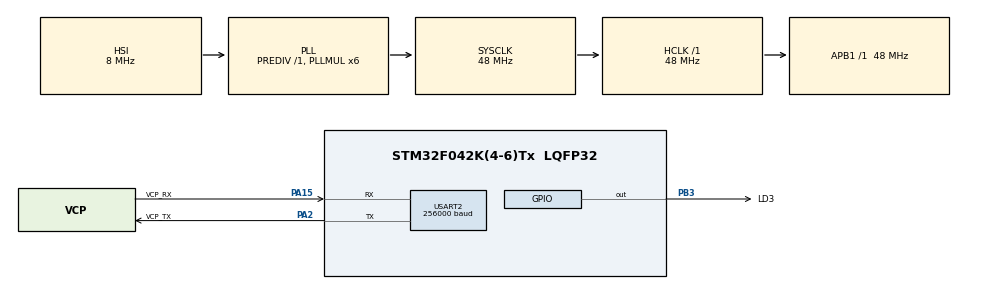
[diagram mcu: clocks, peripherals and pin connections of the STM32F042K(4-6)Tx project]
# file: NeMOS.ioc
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ADC.ContinuousConvMode=ENABLE
ADC.DMAContinuousRequests=ENABLE
ADC.SamplingTime=ADC_SAMPLETIME_239CYCLES_5
Dma.ADC.0.Direction=DMA_PERIPH_TO_MEMORY
Dma.ADC.0.Instance=DMA1_Channel1
Dma.ADC.0.MemDataAlignment=DMA_MDATAALIGN_HALFWORD
Dma.ADC.0.MemInc=DMA_MINC_ENABLE
Dma.ADC.0.Mode=DMA_CIRCULAR
Dma.ADC.0.PeriphDataAlignment=DMA_PDATAALIGN_HALFWORD
Dma.ADC.0.PeriphInc=DMA_PINC_DISABLE
Dma.ADC.0.Priority=DMA_PRIORITY_LOW
Dma.Request0=ADC
Mcu.Family=STM32F0
Mcu.Name=STM32F042K(4-6)Tx
Mcu.Package=LQFP32
Mcu.UserConstants=SYS_TICK_HZ,1000;ADC_CHAN_NO,3
NVIC.DMA1_Channel1_IRQn=true\:0\:0\:false\:false\:true\:false
PA13.GPIO_Label=SWDIO
PA13.Mode=Serial_Wire
PA13.Signal=SYS_SWDIO
PA14.GPIO_Label=SWCLK
PA14.Mode=Serial_Wire
PA14.Signal=SYS_SWCLK
PA15.GPIO_Label=VCP_RX
PA15.Mode=Asynchronous
PA15.Signal=USART2_RX
PA2.GPIO_Label=VCP_TX
PA2.Mode=Asynchronous
PA2.Signal=USART2_TX
PB3.GPIO_Label=LD3
PB3.Signal=GPIO_Output
PF0-OSC_IN.GPIO_Label=MCO
PF0-OSC_IN.Mode=HSE-External-Clock-Source
PF0-OSC_IN.Signal=RCC_OSC_IN
ProjectManager.HeapSize=0x200
ProjectManager.StackSize=0x400
ProjectManager.TargetToolchain=MDK-ARM V5
RCC.AHBFreq_Value=48000000
RCC.APB1Freq_Value=48000000
RCC.APB1TimFreq_Value=48000000
RCC.HCLKFreq_Value=48000000
RCC.PLLMUL=RCC_PLL_MUL6
RCC.SYSCLKFreq_VALUE=48000000
RCC.SYSCLKSource=RCC_SYSCLKSOURCE_PLLCLK
USART2.BaudRate=256000
USART2.VirtualMode-Asynchronous=VM_ASYNC
USART2.WordLength=WORDLENGTH_8B
VP_ADC_TempSens_Input.Mode=IN-TempSens
VP_ADC_Vbat_Input.Mode=IN-Vbat
VP_ADC_Vref_Input.Mode=IN-Vrefint
board=NUCLEO-F042K6

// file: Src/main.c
/**
  ******************************************************************************
  * @file           : main.c
  * @brief          : Main program body
  ******************************************************************************
  ** This notice applies to any and all portions of this file
  * that are not between comment pairs USER CODE BEGIN and
  * USER CODE END. Other portions of this file, whether
  * inserted by the user or by software development tools
  * are owned by their respective copyright owners.
  *
  * COPYRIGHT(c) 2018 STMicroelectronics
  *
  * Redistribution and use in source and binary forms, with or without modification,
  * are permitted provided that the following conditions are met:
  *   1. Redistributions of source code must retain the above copyright notice,
  *      this list of conditions and the following disclaimer.
  *   2. Redistributions in binary form must reproduce the above copyright notice,
  *      this list of conditions and the following disclaimer in the documentation
  *      and/or other materials provided with the distribution.
  *   3. Neither the name of STMicroelectronics nor the names of its contributors
  *      may be used to endorse or promote products derived from this software
  *      without specific prior written permission.
  *
  * THIS SOFTWARE IS PROVIDED BY THE COPYRIGHT HOLDERS AND CONTRIBUTORS "AS IS"
  * AND ANY EXPRESS OR IMPLIED WARRANTIES, INCLUDING, BUT NOT LIMITED TO, THE
  * IMPLIED WARRANTIES OF MERCHANTABILITY AND FITNESS FOR A PARTICULAR PURPOSE ARE
  * DISCLAIMED. IN NO EVENT SHALL THE COPYRIGHT HOLDER OR CONTRIBUTORS BE LIABLE
  * FOR ANY DIRECT, INDIRECT, INCIDENTAL, SPECIAL, EXEMPLARY, OR CONSEQUENTIAL
  * DAMAGES (INCLUDING, BUT NOT LIMITED TO, PROCUREMENT OF SUBSTITUTE GOODS OR
  * SERVICES; LOSS OF USE, DATA, OR PROFITS; OR BUSINESS INTERRUPTION) HOWEVER
  * CAUSED AND ON ANY THEORY OF LIABILITY, WHETHER IN CONTRACT, STRICT LIABILITY,
  * OR TORT (INCLUDING NEGLIGENCE OR OTHERWISE) ARISING IN ANY WAY OUT OF THE USE
  * OF THIS SOFTWARE, EVEN IF ADVISED OF THE POSSIBILITY OF SUCH DAMAGE.
  *
  ******************************************************************************
  */
#include "main.h"
#include "stm32f0xx_hal.h"
#include "adc.h"
#include "dma.h"
#include "usart.h"
#include "gpio.h"

/* USER CODE BEGIN Includes */
#include <stdio.h>
#include <string.h>
#include <stdint.h>
#include <stdlib.h>
#include <assert.h>

#include "los_sys.h"
#include "los_tick.h"
#include "los_task.h"
#include "los_config.h"

#include "los_inspect_entry.h"
#include "los_demo_entry.h"

#include "retarget_io_drv.h"
/* USER CODE END Includes */

/* USER CODE BEGIN PV */
/* Private variables ---------------------------------------------------------*/

/* USER CODE END PV */

void SystemClock_Config(void);

/* USER CODE BEGIN PFP */
/* Private function prototypes -----------------------------------------------*/

/* USER CODE END PFP */

/* USER CODE BEGIN 0 */
__IO uint16_t g_ADCBuf[ADC_CHAN_NO*2];

static uint32_t g_uwboadTaskID;
static  void LOS_BoardExampleTskfunc(void)
{
//	HAL_ADC_Start_DMA(&hadc, (uint32_t*)g_ADCBuf, ADC_CHAN_NO);

	while (1)
	{
//		printf("%u\n",
//		g_ADCBuf[0]
//		);

		LED_Toggle(0);
		(void)LOS_TaskDelay(4000);
	}
}

void LOS_BoardExampleEntry(void)
{
    uint32_t uwRet;
    TSK_INIT_PARAM_S stTaskInitParam;

    (void)memset((void *)(&stTaskInitParam), 0, sizeof(TSK_INIT_PARAM_S));
    stTaskInitParam.pfnTaskEntry = (TSK_ENTRY_FUNC)LOS_BoardExampleTskfunc;
    stTaskInitParam.uwStackSize = LOSCFG_BASE_CORE_TSK_IDLE_STACK_SIZE;
    stTaskInitParam.pcName = "BoardDemo";
    stTaskInitParam.usTaskPrio = 10;
    uwRet = LOS_TaskCreate(&g_uwboadTaskID, &stTaskInitParam);

    if (uwRet != OS_OK)
    {
        return;
    }
    return;
}

extern void LOS_Demo_Entry(void);
extern void LOS_Inspect_Entry(void);

/* USER CODE END 0 */

int main(void)
{
  /* USER CODE BEGIN 1 */
  uint32_t uwRet;

  /* USER CODE END 1 */

  /* MCU Configuration----------------------------------------------------------*/

  /* Reset of all peripherals, Initializes the Flash interface and the Systick. */
  HAL_Init();

  /* Configure the system clock */
  SystemClock_Config();

  /* Initialize all configured peripherals */
  MX_GPIO_Init();
  MX_DMA_Init();
  MX_USART2_UART_Init();
  MX_ADC_Init();
  /* USER CODE BEGIN 2 */
	HAL_ADC_Start_DMA(&hadc, (uint32_t*)g_ADCBuf, ADC_CHAN_NO);

	printf("NeMOS @ %u Hz\n",
		SystemCoreClock
		);

//		printf("%08X CC:%u\n", SCB->CPUID, __ARMCC_VERSION);
//
//		printf("Cortex M%u Rev:%u\n", __CORTEX_M, __CM0_REV);
  /* USER CODE END 2 */
  /*Init LiteOS kernel */
    uwRet = LOS_KernelInit();
    if (uwRet != OS_OK) {
        return OS_NOK;
    }
    /* Enable LiteOS system tick interrupt */
    uwRet = LOS_EnableTick();
    if (uwRet != OS_OK) {
        return OS_NOK;
    }

//    LOS_Demo_Entry();

//    LOS_Inspect_Entry();

    LOS_BoardExampleEntry();

    /* Kernel start to run */
    (void)LOS_Start();
  /* Infinite loop */
  /* USER CODE BEGIN WHILE */
  while (1)
  {
			//Should never come here
//			assert(true);
//		printf("%u %u %u\n",
//		g_ADCBuf[0], g_ADCBuf[1], g_ADCBuf[2]
//		);
//
//		HAL_GPIO_TogglePin(LD3_GPIO_Port, LD3_Pin);
//
//		HAL_Delay(8000);
  /* USER CODE END WHILE */

  }

}

void SystemClock_Config(void)
{

  RCC_OscInitTypeDef RCC_OscInitStruct;
  RCC_ClkInitTypeDef RCC_ClkInitStruct;

    /**Initializes the CPU, AHB and APB busses clocks
    */
  RCC_OscInitStruct.OscillatorType = RCC_OSCILLATORTYPE_HSI|RCC_OSCILLATORTYPE_HSI14;
  RCC_OscInitStruct.HSIState = RCC_HSI_ON;
  RCC_OscInitStruct.HSI14State = RCC_HSI14_ON;
  RCC_OscInitStruct.HSICalibrationValue = 16;
  RCC_OscInitStruct.HSI14CalibrationValue = 16;
  RCC_OscInitStruct.PLL.PLLState = RCC_PLL_ON;
  RCC_OscInitStruct.PLL.PLLSource = RCC_PLLSOURCE_HSI;
  RCC_OscInitStruct.PLL.PLLMUL = RCC_PLL_MUL6;
  RCC_OscInitStruct.PLL.PREDIV = RCC_PREDIV_DIV1;
  if (HAL_RCC_OscConfig(&RCC_OscInitStruct) != HAL_OK)
  {
    _Error_Handler(__FILE__, __LINE__);
  }

    /**Initializes the CPU, AHB and APB busses clocks
    */
  RCC_ClkInitStruct.ClockType = RCC_CLOCKTYPE_HCLK|RCC_CLOCKTYPE_SYSCLK
                              |RCC_CLOCKTYPE_PCLK1;
  RCC_ClkInitStruct.SYSCLKSource = RCC_SYSCLKSOURCE_PLLCLK;
  RCC_ClkInitStruct.AHBCLKDivider = RCC_SYSCLK_DIV1;
  RCC_ClkInitStruct.APB1CLKDivider = RCC_HCLK_DIV1;

  if (HAL_RCC_ClockConfig(&RCC_ClkInitStruct, FLASH_LATENCY_1) != HAL_OK)
  {
    _Error_Handler(__FILE__, __LINE__);
  }

    /**Configure the Systick interrupt time
    */
  HAL_SYSTICK_Config(HAL_RCC_GetHCLKFreq()/1000);

    /**Configure the Systick
    */
  HAL_SYSTICK_CLKSourceConfig(SYSTICK_CLKSOURCE_HCLK);

  /* SysTick_IRQn interrupt configuration */
  HAL_NVIC_SetPriority(SysTick_IRQn, 0, 0);
}

void _Error_Handler(char *file, int line)
{
  while(1)
  {
  }
}

/************************ (C) COPYRIGHT STMicroelectronics *****END OF FILE****/
